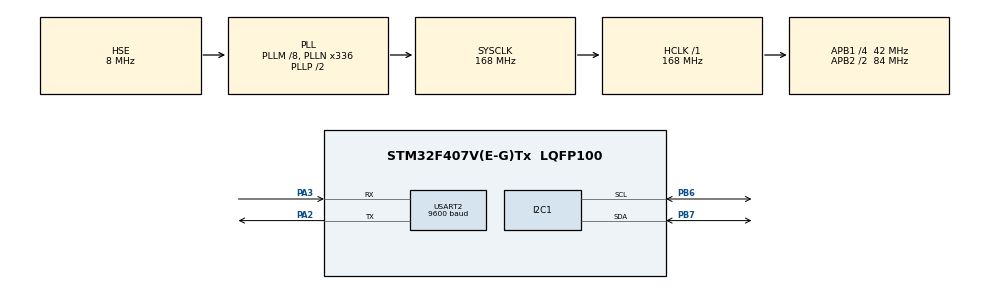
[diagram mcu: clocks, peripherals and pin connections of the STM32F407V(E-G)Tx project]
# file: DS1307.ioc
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Mcu.Family=STM32F4
Mcu.Name=STM32F407V(E-G)Tx
Mcu.Package=LQFP100
NVIC.PriorityGroup=NVIC_PRIORITYGROUP_4
NVIC.USART2_IRQn=true\:0\:0\:false\:false\:true\:true
PA2.Mode=Asynchronous
PA2.Signal=USART2_TX
PA3.Mode=Asynchronous
PA3.Signal=USART2_RX
PB6.Mode=I2C
PB6.Signal=I2C1_SCL
PB7.Mode=I2C
PB7.Signal=I2C1_SDA
PH0-OSC_IN.Mode=HSE-External-Oscillator
PH0-OSC_IN.Signal=RCC_OSC_IN
PH1-OSC_OUT.Mode=HSE-External-Oscillator
PH1-OSC_OUT.Signal=RCC_OSC_OUT
ProjectManager.HeapSize=0x200
ProjectManager.StackSize=0x400
ProjectManager.TargetToolchain=MDK-ARM V5
RCC.48MHZClocksFreq_Value=84000000
RCC.AHBFreq_Value=168000000
RCC.APB1CLKDivider=RCC_HCLK_DIV4
RCC.APB1Freq_Value=42000000
RCC.APB1TimFreq_Value=84000000
RCC.APB2CLKDivider=RCC_HCLK_DIV2
RCC.APB2Freq_Value=84000000
RCC.APB2TimFreq_Value=168000000
RCC.CortexFreq_Value=168000000
RCC.HCLKFreq_Value=168000000
RCC.HSE_VALUE=8000000
RCC.HSI_VALUE=16000000
RCC.LSE_VALUE=32768
RCC.PLLM=8
RCC.PLLN=336
RCC.PLLSourceVirtual=RCC_PLLSOURCE_HSE
RCC.SYSCLKFreq_VALUE=168000000
RCC.SYSCLKSource=RCC_SYSCLKSOURCE_PLLCLK
RCC.VCOOutputFreq_Value=336000000
USART2.BaudRate=9600
USART2.VirtualMode=VM_ASYNC
board=DS1307

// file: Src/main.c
/**
  ******************************************************************************
  * @file           : main.c
  * @brief          : Main program body
  ******************************************************************************
  ** This notice applies to any and all portions of this file
  * that are not between comment pairs USER CODE BEGIN and
  * USER CODE END. Other portions of this file, whether
  * inserted by the user or by software development tools
  * are owned by their respective copyright owners.
  *
  * COPYRIGHT(c) 2018 STMicroelectronics
  *
  * Redistribution and use in source and binary forms, with or without modification,
  * are permitted provided that the following conditions are met:
  *   1. Redistributions of source code must retain the above copyright notice,
  *      this list of conditions and the following disclaimer.
  *   2. Redistributions in binary form must reproduce the above copyright notice,
  *      this list of conditions and the following disclaimer in the documentation
  *      and/or other materials provided with the distribution.
  *   3. Neither the name of STMicroelectronics nor the names of its contributors
  *      may be used to endorse or promote products derived from this software
  *      without specific prior written permission.
  *
  * THIS SOFTWARE IS PROVIDED BY THE COPYRIGHT HOLDERS AND CONTRIBUTORS "AS IS"
  * AND ANY EXPRESS OR IMPLIED WARRANTIES, INCLUDING, BUT NOT LIMITED TO, THE
  * IMPLIED WARRANTIES OF MERCHANTABILITY AND FITNESS FOR A PARTICULAR PURPOSE ARE
  * DISCLAIMED. IN NO EVENT SHALL THE COPYRIGHT HOLDER OR CONTRIBUTORS BE LIABLE
  * FOR ANY DIRECT, INDIRECT, INCIDENTAL, SPECIAL, EXEMPLARY, OR CONSEQUENTIAL
  * DAMAGES (INCLUDING, BUT NOT LIMITED TO, PROCUREMENT OF SUBSTITUTE GOODS OR
  * SERVICES; LOSS OF USE, DATA, OR PROFITS; OR BUSINESS INTERRUPTION) HOWEVER
  * CAUSED AND ON ANY THEORY OF LIABILITY, WHETHER IN CONTRACT, STRICT LIABILITY,
  * OR TORT (INCLUDING NEGLIGENCE OR OTHERWISE) ARISING IN ANY WAY OUT OF THE USE
  * OF THIS SOFTWARE, EVEN IF ADVISED OF THE POSSIBILITY OF SUCH DAMAGE.
  *
  ******************************************************************************
  */
#include "main.h"
#include "stm32f4xx_hal.h"
#include "ds1307.h"
#include"stdio.h"

I2C_HandleTypeDef hi2c1;
DS1307_Handle ds1307;
DS1307_TIME time;
I2C_HandleTypeDef i2c_handle;

UART_HandleTypeDef huart2;

/* USER CODE BEGIN PV */
/* Private variables ---------------------------------------------------------*/
uint8_t data[]="HELLO WORLD\n"; // transmit
/* USER CODE END PV */

void SystemClock_Config(void);
static void MX_GPIO_Init(void);
static void MX_USART2_UART_Init(void);
static void MX_I2C1_Init(void);

/* USER CODE BEGIN PFP */
/* Private function prototypes -----------------------------------------------*/
/* Private function prototypes -----------------------------------------------*/
#ifdef __GNUC__
 /* With GCC/RAISONANCE, small printf (option LD Linker->Libraries->Small printf
 set to 'Yes') calls __io_putchar() */
 #define PUTCHAR_PROTOTYPE int __io_putchar(int ch)
#else
 #define PUTCHAR_PROTOTYPE int fputc(int ch, FILE *f)
#endif /* __GNUC__ */

/**
 * @brief Retargets the C library printf function to the USART.
 * @param None
 * @retval None
 */
PUTCHAR_PROTOTYPE
{
 /* Place your implementation of fputc here */
 /* e.g. write a character to the USART */
 HAL_UART_Transmit(&huart2, (uint8_t *)&ch, 1, 100);

 return ch;
}
/* USER CODE END PFP */

/* USER CODE END PFP */

DS1307_RESULT confDS1307(void) {

	ds1307.i2c = &i2c_handle;
	ds1307.DS1307_ADDRESS = 0xD0;
	ds1307.DS1307_CLOCK = 100000;
	ds1307.DS1307_I2Cx = I2C1;
	ds1307.TIMEOUT = 1000;
	DS1307_RESULT res;
	res = DS1307_Init(&ds1307);
	if (res != DS1307_RES_OK) {
		return DS1307_RES_ERROR;
	}
	res = DS1307_ClockResume(&ds1307);
	if (res != DS1307_RES_OK) {
		return DS1307_RES_ERROR;
	}
	res = DS1307_EnableSquareWave(&ds1307);
	if (res != DS1307_RES_OK) {
		return DS1307_RES_ERROR;
	}
	res = DS1307_SelectRate(&ds1307, DS1307_RATE_1HZ);
	if (res != DS1307_RES_OK) {
		return DS1307_RES_ERROR;
	}
	return DS1307_RES_OK;
}

int main(void)
{

  /* MCU Configuration----------------------------------------------------------*/

  /* Reset of all peripherals, Initializes the Flash interface and the Systick. */
  HAL_Init();

  /* Configure the system clock */
  SystemClock_Config();

  /* Initialize all configured peripherals */
  MX_GPIO_Init();
  MX_USART2_UART_Init();
  MX_I2C1_Init();
	if (confDS1307() != DS1307_RES_OK)
		{
			printf("loi roi DS1307 \r\n");
		}
/*
	time.hour=18;
	time.minute=26;
	time.second=30;
	time.date=4;
	time.month=5;
	time.year=2018;
DS1307_SetTime(&ds1307,time);
*/

	printf("Hello World Cuong dz\r\n");

  /* Infinite loop */
  while (1)
  {

  /* USER CODE BEGIN 3 */
		time = DS1307_GetTime(&ds1307);
		printf("");
		printf("\r\nGio hien tai: %d:%d:%d | %d/%d/%d\r\n",time.hour,time.minute,time.second,time.date,time.month,time.year);
		HAL_Delay(1000);

  }
  /* USER CODE END 3 */

}

void SystemClock_Config(void)
{

  RCC_OscInitTypeDef RCC_OscInitStruct;
  RCC_ClkInitTypeDef RCC_ClkInitStruct;

    /**Configure the main internal regulator output voltage
    */
  __HAL_RCC_PWR_CLK_ENABLE();

  __HAL_PWR_VOLTAGESCALING_CONFIG(PWR_REGULATOR_VOLTAGE_SCALE1);

    /**Initializes the CPU, AHB and APB busses clocks
    */
  RCC_OscInitStruct.OscillatorType = RCC_OSCILLATORTYPE_HSE;
  RCC_OscInitStruct.HSEState = RCC_HSE_ON;
  RCC_OscInitStruct.PLL.PLLState = RCC_PLL_ON;
  RCC_OscInitStruct.PLL.PLLSource = RCC_PLLSOURCE_HSE;
  RCC_OscInitStruct.PLL.PLLM = 8;
  RCC_OscInitStruct.PLL.PLLN = 336;
  RCC_OscInitStruct.PLL.PLLP = RCC_PLLP_DIV2;
  RCC_OscInitStruct.PLL.PLLQ = 4;
  if (HAL_RCC_OscConfig(&RCC_OscInitStruct) != HAL_OK)
  {
    _Error_Handler(__FILE__, __LINE__);
  }

    /**Initializes the CPU, AHB and APB busses clocks
    */
  RCC_ClkInitStruct.ClockType = RCC_CLOCKTYPE_HCLK|RCC_CLOCKTYPE_SYSCLK
                              |RCC_CLOCKTYPE_PCLK1|RCC_CLOCKTYPE_PCLK2;
  RCC_ClkInitStruct.SYSCLKSource = RCC_SYSCLKSOURCE_PLLCLK;
  RCC_ClkInitStruct.AHBCLKDivider = RCC_SYSCLK_DIV1;
  RCC_ClkInitStruct.APB1CLKDivider = RCC_HCLK_DIV4;
  RCC_ClkInitStruct.APB2CLKDivider = RCC_HCLK_DIV2;

  if (HAL_RCC_ClockConfig(&RCC_ClkInitStruct, FLASH_LATENCY_5) != HAL_OK)
  {
    _Error_Handler(__FILE__, __LINE__);
  }

    /**Configure the Systick interrupt time
    */
  HAL_SYSTICK_Config(HAL_RCC_GetHCLKFreq()/1000);

    /**Configure the Systick
    */
  HAL_SYSTICK_CLKSourceConfig(SYSTICK_CLKSOURCE_HCLK);

  /* SysTick_IRQn interrupt configuration */
  HAL_NVIC_SetPriority(SysTick_IRQn, 0, 0);
}

/* I2C1 init function */
static void MX_I2C1_Init(void)
{

  hi2c1.Instance = I2C1;
  hi2c1.Init.ClockSpeed = 100000;
  hi2c1.Init.DutyCycle = I2C_DUTYCYCLE_2;
  hi2c1.Init.OwnAddress1 = 0;
  hi2c1.Init.AddressingMode = I2C_ADDRESSINGMODE_7BIT;
  hi2c1.Init.DualAddressMode = I2C_DUALADDRESS_DISABLE;
  hi2c1.Init.OwnAddress2 = 0;
  hi2c1.Init.GeneralCallMode = I2C_GENERALCALL_DISABLE;
  hi2c1.Init.NoStretchMode = I2C_NOSTRETCH_DISABLE;
  if (HAL_I2C_Init(&hi2c1) != HAL_OK)
  {
    _Error_Handler(__FILE__, __LINE__);
  }

}

/* USART2 init function */
static void MX_USART2_UART_Init(void)
{

  huart2.Instance = USART2;
  huart2.Init.BaudRate = 9600;
  huart2.Init.WordLength = UART_WORDLENGTH_8B;
  huart2.Init.StopBits = UART_STOPBITS_1;
  huart2.Init.Parity = UART_PARITY_NONE;
  huart2.Init.Mode = UART_MODE_TX_RX;
  huart2.Init.HwFlowCtl = UART_HWCONTROL_NONE;
  huart2.Init.OverSampling = UART_OVERSAMPLING_16;
  if (HAL_UART_Init(&huart2) != HAL_OK)
  {
    _Error_Handler(__FILE__, __LINE__);
  }

}

/** Configure pins as
        * Analog
        * Input
        * Output
        * EVENT_OUT
        * EXTI
*/
static void MX_GPIO_Init(void)
{

  /* GPIO Ports Clock Enable */
  __HAL_RCC_GPIOH_CLK_ENABLE();
  __HAL_RCC_GPIOA_CLK_ENABLE();
  __HAL_RCC_GPIOB_CLK_ENABLE();

}

void _Error_Handler(char *file, int line)
{
  while(1)
  {
  }
}

/************************ (C) COPYRIGHT STMicroelectronics *****END OF FILE****/
